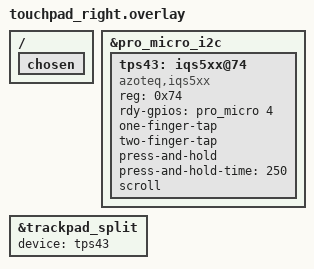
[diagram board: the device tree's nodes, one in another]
/*
 * Azoteq TPS43 touchpad for the right (peripheral) half. Applied after the
 * lily58_right shield overlay, so it can remove the shield's OLED node.
 */

#include "../../../lily58_touchpad.dtsi"

/* No SSD1306 OLED on this half: the I2C bus (P0.17 SDA / P0.20 SCL) hosts the touchpad. */
/ {
    chosen {
        /delete-property/ zephyr,display;
    };
};

/delete-node/ &oled;

&pro_micro_i2c {
    status = "okay";

    tps43: iqs5xx@74 {
        compatible = "azoteq,iqs5xx";
        reg = <0x74>;
        status = "okay";

        /* RDY on P0.22 (pro_micro 4). RST is not wired. */
        rdy-gpios = <&pro_micro 4 GPIO_ACTIVE_HIGH>;

        one-finger-tap;
        two-finger-tap;
        press-and-hold;
        press-and-hold-time = <250>;
        scroll;
    };
};

/* Forward the touchpad's events to the central over the split link. */
&trackpad_split {
    device = <&tps43>;
};
